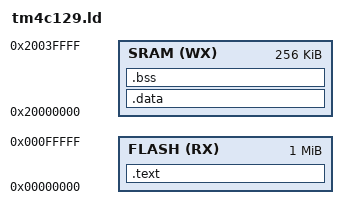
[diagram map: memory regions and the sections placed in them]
/******************************************************************************
 *
 * Default Linker script for the Texas Instruments TM4C1294NCPDT
 *
 * This is derived from revision 12770 of the TivaWare Library.
 *
 *****************************************************************************/

MEMORY
{
    FLASH (RX) : ORIGIN = 0x00000000, LENGTH = 0x00100000
    SRAM (WX)  : ORIGIN = 0x20000000, LENGTH = 0x00040000
}

SECTIONS
{
    .text :
    {
        _text = .;
        KEEP(*(.isr_vector))
        *(.text*)
        *(.rodata*)
        _etext = .;
    } > FLASH

    .data : AT(ADDR(.text) + SIZEOF(.text))
    {
        _data = .;
        *(vtable)
        *(.data*)
        _edata = .;
    } > SRAM

    .bss :
    {
        _bss = .;
        *(.bss*)
        *(COMMON)
        _ebss = .;
    } > SRAM
}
